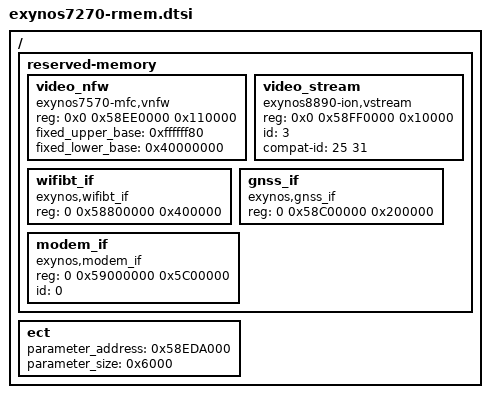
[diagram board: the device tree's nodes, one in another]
/*
 * SAMSUNG EXYNOS device tree source for reserved-memory
 *
 * Copyright (c) 2015 Samsung Electronics Co., Ltd.
 *		http://www.samsung.com
 *
 * This program is free software; you can redistribute it and/or modify
 * it under the terms of the GNU General Public License version 2 as
 * published by the Free Software Foundation.
*/

/ {
	reserved-memory {
		#address-cells = <2>;
		#size-cells = <1>;
		ranges;

		video_nfw {
			compatible = "exynos7570-mfc,vnfw";
			reg = <0x0 0x58EE0000 0x110000>;
			fixed_upper_base = <0xffffff80>;
			fixed_lower_base = <0x40000000>;
		};

		video_stream {
			compatible = "exynos8890-ion,vstream";
			reg = <0x0 0x58FF0000 0x10000>;
			id = <3>;
			compat-id = <25 31>;
		};

		wifibt_if {
			compatible = "exynos,wifibt_if";
			reg = <0 0x58800000 0x400000>;
		};

		gnss_if {
			compatible = "exynos,gnss_if";
			reg = <0 0x58C00000 0x200000>;
		};

		modem_if {
			compatible = "exynos,modem_if";
			reg = <0 0x59000000 0x5C00000>;
			id = <0>;
		};

	};

	ect {
		parameter_address = <0x58EDA000>;
		parameter_size = <0x6000>;
	};
};
